AUTOSAR XML (schema 00046)
package /ComponentTypes
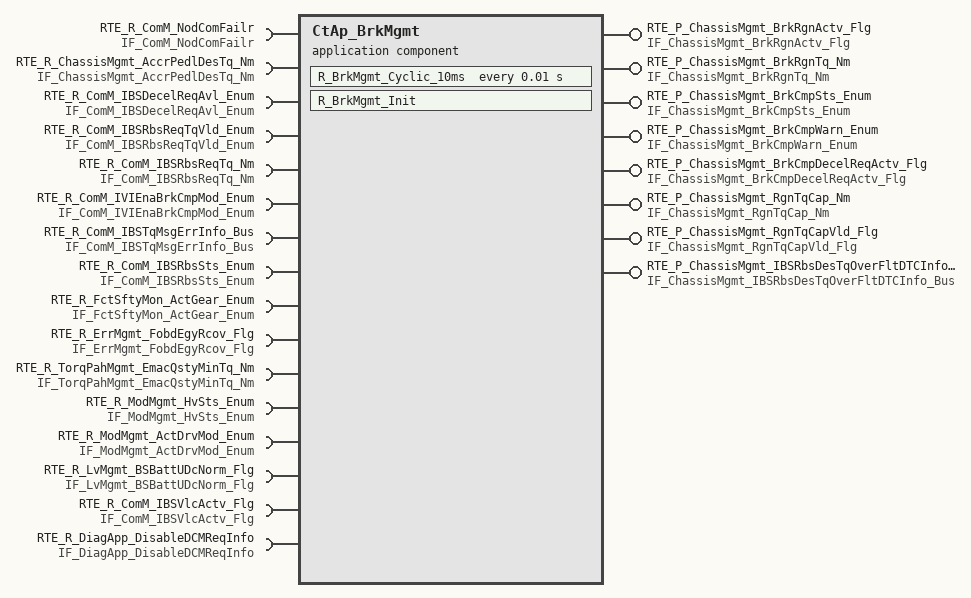
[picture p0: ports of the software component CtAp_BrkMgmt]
  application sw component type CtAp_BrkMgmt
    13 x require port:
      RTE_R_ComM_NodComFailr: required-interface=IF_ComM_NodComFailr
        required-com-specs:
          data-element=tec_ComM_SGWNodComFailr_Flg, filter=data-filter-type=ALWAYS, init-value=0
          data-element=tec_ComM_CGWNodComFailr_Flg, filter=data-filter-type=ALWAYS, init-value=0
          data-element=tec_ComM_TCUNodComFailr_Flg, filter=data-filter-type=ALWAYS, init-value=0
          data-element=tec_ComM_BCMNodComFailr_Flg, filter=data-filter-type=ALWAYS, init-value=0
          data-element=tec_ComM_PRNDNodComFailr_Flg, filter=data-filter-type=ALWAYS, init-value=0
          data-element=tec_ComM_IVINodComFailr_Flg, filter=data-filter-type=ALWAYS, init-value=0
          data-element=tec_ComM_DCDCNodComFailr_Flg, filter=data-filter-type=ALWAYS, init-value=0
          data-element=tec_ComM_OBCNodComFailr_Flg, filter=data-filter-type=ALWAYS, init-value=0
          data-element=tec_ComM_CHIBSNodComFailr_Flg, filter=data-filter-type=ALWAYS, init-value=0
          data-element=tec_ComM_MCUNodComFailr_Flg, filter=data-filter-type=ALWAYS, init-value=0
          data-element=tec_ComM_EVCOMNodComFailr_Flg, filter=data-filter-type=ALWAYS, init-value=0
          data-element=tec_ComM_EPTIBSNodComFailr_Flg, filter=data-filter-type=ALWAYS, init-value=0
          data-element=tec_ComM_DCMNodComFailr_Flg, filter=data-filter-type=ALWAYS, init-value=0
          data-element=tec_ComM_BMSNodComFailr_Flg, filter=data-filter-type=ALWAYS, init-value=0
          data-element=tec_ComM_ACUNodComFailr_Flg, filter=data-filter-type=ALWAYS, init-value=0
          data-element=tec_ComM_APTCNodComFailr_Flg, filter=data-filter-type=ALWAYS, init-value=0
          data-element=tec_ComM_ADCUNodComFailr_Flg, filter=data-filter-type=ALWAYS, init-value=0
          data-element=tec_ComM_DCMRRNodComFailr_Flg, filter=data-filter-type=ALWAYS, init-value=0
          data-element=tec_ComM_DCMRLNodComFailr_Flg, filter=data-filter-type=ALWAYS, init-value=0
          data-element=tec_ComM_DCMFRNodComFailr_Flg, filter=data-filter-type=ALWAYS, init-value=0
          data-element=tec_ComM_DCMFLNodComFailr_Flg, filter=data-filter-type=ALWAYS, init-value=0
          data-element=tec_ComM_SGWCHNodComFailr_Flg, init-value=0
      RTE_R_ChassisMgmt_AccrPedlDesTq_Nm: nonqueued-receiver-com-spec{data-element=tec_ChassisMgmt_AccrPedlDesTq_Nm, filter=data-filter-type=ALWAYS, init-value=0}, required-interface=IF_ChassisMgmt_AccrPedlDesTq_Nm
      RTE_R_ComM_IBSDecelReqAvl_Enum: nonqueued-receiver-com-spec{data-element=tec_ComM_IBSDecelReqAvl_Enum, filter=data-filter-type=ALWAYS, init-value=0}, required-interface=IF_ComM_IBSDecelReqAvl_Enum
      RTE_R_ComM_IBSRbsReqTqVld_Enum: nonqueued-receiver-com-spec{data-element=tec_ComM_IBSRbsReqTqVld_Enum, filter=data-filter-type=ALWAYS, init-value=0}, required-interface=IF_ComM_IBSRbsReqTqVld_Enum
      RTE_R_ComM_IBSRbsReqTq_Nm: nonqueued-receiver-com-spec{data-element=tec_ComM_IBSRbsReqTq_Nm, filter=data-filter-type=ALWAYS, init-value=0}, required-interface=IF_ComM_IBSRbsReqTq_Nm
      RTE_R_ComM_IVIEnaBrkCmpMod_Enum: nonqueued-receiver-com-spec{data-element=tec_ComM_IVIEnaBrkCmpMod_Enum, filter=data-filter-type=ALWAYS, init-value=0}, required-interface=IF_ComM_IVIEnaBrkCmpMod_Enum
      RTE_R_ComM_IBSTqMsgErrInfo_Bus: required-interface=IF_ComM_IBSTqMsgErrInfo_Bus
        required-com-specs:
          data-element=tec_ComM_IBSTqCRCDTCInfo_Bus, filter=data-filter-type=ALWAYS, init-value=fields=[ComM_MonStatIBSTqCRCDTCErrorInfo:0, ComM_MonResIBSTqCRCDTCErrorInfo:0, ComM_ErrStatIBSTqCRCDTCErrorInfo:0, ComM_ErrResIBSTqCRCDTCErrorInfo:0]
          data-element=tec_ComM_IBSTqTimeoutDTCInfo_Bus, filter=data-filter-type=ALWAYS, init-value=fields=[ComM_MonStatIBSTqTimeoutDTCErrorInfo:0, ComM_MonResIBSTqTimeoutDTCErrorInfo:0, ComM_ErrStatIBSTqTimeoutDTCErrorInfo:0, ComM_ErrResIBSTqTimeoutDTCErrorInfo:0]
          data-element=tec_ComM_IBSTqCRCInfo_Bus, filter=data-filter-type=ALWAYS, init-value=fields=[ComM_MonStatIBSTqCRCErrorInfo:0, ComM_MonResIBSTqCRCErrorInfo:0, ComM_ErrStatIBSTqCRCErrorInfo:0, ComM_ErrResIBSTqCRCErrorInfo:0]
          data-element=tec_ComM_IBSTqE2ETimeoutInfo_Bus, filter=data-filter-type=ALWAYS, init-value=fields=[ComM_MonStatIBSTqE2ETimeoutInfo:0, ComM_MonResIBSTqE2ETimeoutInfo:0, ComM_ErrStatIBSTqE2ETimeoutInfo:0, ComM_ErrResIBSTqE2ETimeoutInfo:0]
      RTE_R_ComM_IBSRbsSts_Enum: nonqueued-receiver-com-spec{data-element=tec_ComM_IBSRbsSts_Enum, filter=data-filter-type=ALWAYS, init-value=0}, required-interface=IF_ComM_IBSRbsSts_Enum
      RTE_R_FctSftyMon_ActGear_Enum: nonqueued-receiver-com-spec{data-element=tec_FctSftyMon_ActGear_Enum, filter=data-filter-type=ALWAYS, init-value=0}, required-interface=IF_FctSftyMon_ActGear_Enum
      RTE_R_ErrMgmt_FobdEgyRcov_Flg: nonqueued-receiver-com-spec{data-element=tec_ErrMgmt_FobdEgyRcov_Flg, filter=data-filter-type=ALWAYS, init-value=0}, required-interface=IF_ErrMgmt_FobdEgyRcov_Flg
      RTE_R_TorqPahMgmt_EmacQstyMinTq_Nm: nonqueued-receiver-com-spec{data-element=tec_TorqPahMgmt_EmacQstyMinTq_Nm, filter=data-filter-type=ALWAYS, init-value=0}, required-interface=IF_TorqPahMgmt_EmacQstyMinTq_Nm
      RTE_R_ModMgmt_HvSts_Enum: nonqueued-receiver-com-spec{data-element=tec_ModMgmt_HvSts_Enum, filter=data-filter-type=ALWAYS, init-value=0}, required-interface=IF_ModMgmt_HvSts_Enum
      RTE_R_ModMgmt_ActDrvMod_Enum: nonqueued-receiver-com-spec{data-element=tec_ModMgmt_ActDrvMod_Enum, filter=data-filter-type=ALWAYS, init-value=0}, required-interface=IF_ModMgmt_ActDrvMod_Enum
    8 x provide port:
      RTE_P_ChassisMgmt_BrkRgnActv_Flg: nonqueued-sender-com-spec{data-element=tec_ChassisMgmt_BrkRgnActv_Flg, init-value=0}, provided-interface=IF_ChassisMgmt_BrkRgnActv_Flg
      RTE_P_ChassisMgmt_BrkRgnTq_Nm: nonqueued-sender-com-spec{data-element=tec_ChassisMgmt_BrkRgnTq_Nm, init-value=0}, provided-interface=IF_ChassisMgmt_BrkRgnTq_Nm
      RTE_P_ChassisMgmt_BrkCmpSts_Enum: nonqueued-sender-com-spec{data-element=tec_ChassisMgmt_BrkCmpSts_Enum, init-value=0}, provided-interface=IF_ChassisMgmt_BrkCmpSts_Enum
      RTE_P_ChassisMgmt_BrkCmpWarn_Enum: nonqueued-sender-com-spec{data-element=tec_ChassisMgmt_BrkCmpWarn_Enum, init-value=0}, provided-interface=IF_ChassisMgmt_BrkCmpWarn_Enum
      RTE_P_ChassisMgmt_BrkCmpDecelReqActv_Flg: nonqueued-sender-com-spec{data-element=tec_ChassisMgmt_BrkCmpDecelReqActv_Flg, init-value=0}, provided-interface=IF_ChassisMgmt_BrkCmpDecelReqActv_Flg
      RTE_P_ChassisMgmt_RgnTqCap_Nm: nonqueued-sender-com-spec{data-element=tec_ChassisMgmt_RgnTqCap_Nm, init-value=0}, provided-interface=IF_ChassisMgmt_RgnTqCap_Nm
      RTE_P_ChassisMgmt_RgnTqCapVld_Flg: nonqueued-sender-com-spec{data-element=tec_ChassisMgmt_RgnTqCapVld_Flg, init-value=0}, provided-interface=IF_ChassisMgmt_RgnTqCapVld_Flg
      RTE_P_ChassisMgmt_IBSRbsDesTqOverFltDTCInfo_Bus: nonqueued-sender-com-spec{data-element=tec_ChassisMgmt_IBSRbsDesTqOverFltDTCInfo_Bus, init-value=fields=[ChassisMgmt_MonStatIBSRbsDesTqOverFltDTCInfo:0, ChassisMgmt_MonResIBSRbsDesTqOverFltDTCInfo:0, ChassisMgmt_ErrStatIBSRbsDesTqOverFltDTCInfo:0, ChassisMgmt_ErrResIBSRbsDesTqOverFltDTCInfo:0]}, provided-interface=IF_ChassisMgmt_IBSRbsDesTqOverFltDTCInfo_Bus
    require port RTE_R_LvMgmt_BSBattUDcNorm_Flg: nonqueued-receiver-com-spec{data-element=tec_LvMgmt_BSBattUDcNorm_Flg, filter=data-filter-type=ALWAYS, init-value=0}, required-interface=IF_LvMgmt_BSBattUDcNorm_Flg
    require port RTE_R_ComM_IBSVlcActv_Flg: nonqueued-receiver-com-spec{data-element=tec_ComM_IBSVlcActv_Flg, filter=data-filter-type=ALWAYS, init-value=0}, required-interface=IF_ComM_IBSVlcActv_Flg
    require port RTE_R_DiagApp_DisableDCMReqInfo: nonqueued-receiver-com-spec{data-element=tec_DiagApp_DisableDCMReqInfo, filter=data-filter-type=ALWAYS, init-value=0}, required-interface=IF_DiagApp_DisableDCMReqInfo
    provide/require port RTE_RP_ChassisMgmtInfo:
      nv-provide-com-spec{ram-block-init-value=fields=[ChassisMgmt_BrkCmpStsInfo:2, ChassisMgmt_FillAdressInfo:0], rom-block-init-value=fields=[ChassisMgmt_BrkCmpStsInfo:2, ChassisMgmt_FillAdressInfo:0], variable=tec_ChassisMgmtInfo}
      nv-require-com-spec{init-value=fields=[ChassisMgmt_BrkCmpStsInfo:2, ChassisMgmt_FillAdressInfo:0], variable=tec_ChassisMgmtInfo}
      provided-required-interface=IF_ChassisMgmtInfo
    behavior CtAp_BrkMgmt_InternalBehavior
      timing event TMT_R_BrkMgmt_Cyclic_10ms: start-on-event=R_BrkMgmt_Cyclic_10ms, period=0.01
      init event CtAp_BrkMgmt_InitEvent: start-on-event=R_BrkMgmt_Init
      runnable R_BrkMgmt_Cyclic_10ms
        data-receive-point-by-arguments:
          19 x access:
            REC_RTE_R_ComM_IBSTqMsgErrInfo_Bus_tec_ComM_IBSTqE2ETimeoutInfo_Bus: accessed-variable=RTE_R_ComM_IBSTqMsgErrInfo_Bus.tec_ComM_IBSTqE2ETimeoutInfo_Bus
            REC_RTE_R_ComM_IVIEnaBrkCmpMod_Enum_tec_ComM_IVIEnaBrkCmpMod_Enum: accessed-variable=RTE_R_ComM_IVIEnaBrkCmpMod_Enum.tec_ComM_IVIEnaBrkCmpMod_Enum
            REC_RTE_R_ComM_NodComFailr_tec_ComM_CHIBSNodComFailr_Flg: accessed-variable=RTE_R_ComM_NodComFailr.tec_ComM_CHIBSNodComFailr_Flg
            REC_RTE_R_ComM_NodComFailr_tec_ComM_IVINodComFailr_Flg: accessed-variable=RTE_R_ComM_NodComFailr.tec_ComM_IVINodComFailr_Flg
            REC_RTE_R_ErrMgmt_FobdEgyRcov_Flg_tec_ErrMgmt_FobdEgyRcov_Flg: accessed-variable=RTE_R_ErrMgmt_FobdEgyRcov_Flg.tec_ErrMgmt_FobdEgyRcov_Flg
            REC_RTE_R_FctSftyMon_ActGear_Enum_tec_FctSftyMon_ActGear_Enum: accessed-variable=RTE_R_FctSftyMon_ActGear_Enum.tec_FctSftyMon_ActGear_Enum
            REC_RTE_R_ModMgmt_ActDrvMod_Enum_tec_ModMgmt_ActDrvMod_Enum: accessed-variable=RTE_R_ModMgmt_ActDrvMod_Enum.tec_ModMgmt_ActDrvMod_Enum
            REC_RTE_R_ModMgmt_HvSts_Enum_tec_ModMgmt_HvSts_Enum: accessed-variable=RTE_R_ModMgmt_HvSts_Enum.tec_ModMgmt_HvSts_Enum
            REC_RTE_R_TorqPahMgmt_EmacQstyMinTq_Nm_tec_TorqPahMgmt_EmacQstyMinTq_Nm: accessed-variable=RTE_R_TorqPahMgmt_EmacQstyMinTq_Nm.tec_TorqPahMgmt_EmacQstyMinTq_Nm
            REC_RTE_R_ChassisMgmt_AccrPedlDesTq_Nm_tec_ChassisMgmt_AccrPedlDesTq_Nm: accessed-variable=RTE_R_ChassisMgmt_AccrPedlDesTq_Nm.tec_ChassisMgmt_AccrPedlDesTq_Nm
            REC_RTE_R_ComM_IBSDecelReqAvl_Enum_tec_ComM_IBSDecelReqAvl_Enum: accessed-variable=RTE_R_ComM_IBSDecelReqAvl_Enum.tec_ComM_IBSDecelReqAvl_Enum
            REC_RTE_R_ComM_IBSRbsReqTqVld_Enum_tec_ComM_IBSRbsReqTqVld_Enum: accessed-variable=RTE_R_ComM_IBSRbsReqTqVld_Enum.tec_ComM_IBSRbsReqTqVld_Enum
            REC_RTE_R_ComM_IBSRbsReqTq_Nm_tec_ComM_IBSRbsReqTq_Nm: accessed-variable=RTE_R_ComM_IBSRbsReqTq_Nm.tec_ComM_IBSRbsReqTq_Nm
            REC_RTE_R_ComM_IBSRbsSts_Enum_tec_ComM_IBSRbsSts_Enum: accessed-variable=RTE_R_ComM_IBSRbsSts_Enum.tec_ComM_IBSRbsSts_Enum
            REC_RTE_R_ComM_IBSTqMsgErrInfo_Bus_tec_ComM_IBSTqCRCInfo_Bus: accessed-variable=RTE_R_ComM_IBSTqMsgErrInfo_Bus.tec_ComM_IBSTqCRCInfo_Bus
            REC_RTE_R_LvMgmt_BSBattUDcNorm_Flg_tec_LvMgmt_BSBattUDcNorm_Flg: accessed-variable=RTE_R_LvMgmt_BSBattUDcNorm_Flg.tec_LvMgmt_BSBattUDcNorm_Flg
            REC_RTE_R_ComM_IBSVlcActv_Flg_tec_ComM_IBSVlcActv_Flg: accessed-variable=RTE_R_ComM_IBSVlcActv_Flg.tec_ComM_IBSVlcActv_Flg
            REC_RTE_R_DiagApp_DisableDCMReqInfo_tec_DiagApp_DisableDCMReqInfo: accessed-variable=RTE_R_DiagApp_DisableDCMReqInfo.tec_DiagApp_DisableDCMReqInfo
            REC_RTE_RP_ChassisMgmtInfo_tec_ChassisMgmtInfo: accessed-variable=RTE_RP_ChassisMgmtInfo.tec_ChassisMgmtInfo
        data-send-points:
          9 x access:
            SEND_RTE_P_ChassisMgmt_BrkCmpDecelReqActv_Flg_tec_ChassisMgmt_BrkCmpDecelReqActv_Flg: accessed-variable=RTE_P_ChassisMgmt_BrkCmpDecelReqActv_Flg.tec_ChassisMgmt_BrkCmpDecelReqActv_Flg
            SEND_RTE_P_ChassisMgmt_BrkCmpSts_Enum_tec_ChassisMgmt_BrkCmpSts_Enum: accessed-variable=RTE_P_ChassisMgmt_BrkCmpSts_Enum.tec_ChassisMgmt_BrkCmpSts_Enum
            SEND_RTE_P_ChassisMgmt_BrkCmpWarn_Enum_tec_ChassisMgmt_BrkCmpWarn_Enum: accessed-variable=RTE_P_ChassisMgmt_BrkCmpWarn_Enum.tec_ChassisMgmt_BrkCmpWarn_Enum
            SEND_RTE_P_ChassisMgmt_BrkRgnActv_Flg_tec_ChassisMgmt_BrkRgnActv_Flg: accessed-variable=RTE_P_ChassisMgmt_BrkRgnActv_Flg.tec_ChassisMgmt_BrkRgnActv_Flg
            SEND_RTE_P_ChassisMgmt_BrkRgnTq_Nm_tec_ChassisMgmt_BrkRgnTq_Nm: accessed-variable=RTE_P_ChassisMgmt_BrkRgnTq_Nm.tec_ChassisMgmt_BrkRgnTq_Nm
            SEND_RTE_P_ChassisMgmt_RgnTqCapVld_Flg_tec_ChassisMgmt_RgnTqCapVld_Flg: accessed-variable=RTE_P_ChassisMgmt_RgnTqCapVld_Flg.tec_ChassisMgmt_RgnTqCapVld_Flg
            SEND_RTE_P_ChassisMgmt_RgnTqCap_Nm_tec_ChassisMgmt_RgnTqCap_Nm: accessed-variable=RTE_P_ChassisMgmt_RgnTqCap_Nm.tec_ChassisMgmt_RgnTqCap_Nm
            SEND_RTE_P_ChassisMgmt_IBSRbsDesTqOverFltDTCInfo_Bus_tec_ChassisMgmt_IBSRbsDesTqOverFltDTCInfo_Bus: accessed-variable=RTE_P_ChassisMgmt_IBSRbsDesTqOverFltDTCInfo_Bus.tec_ChassisMgmt_IBSRbsDesTqOverFltDTCInfo_Bus
            SEND_RTE_RP_ChassisMgmtInfo_tec_ChassisMgmtInfo: accessed-variable=RTE_RP_ChassisMgmtInfo.tec_ChassisMgmtInfo
      runnable R_BrkMgmt_Init
  swc implementation CtAp_BrkMgmt_Implementation: behavior=CtAp_BrkMgmt_InternalBehavior
